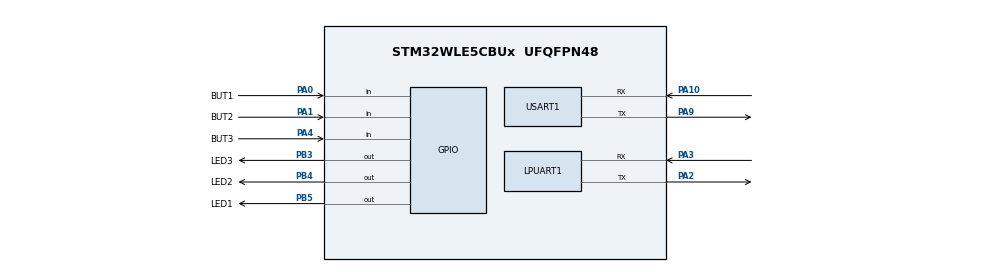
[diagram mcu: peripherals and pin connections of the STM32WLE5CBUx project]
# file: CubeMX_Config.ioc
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Mcu.Family=STM32WL
Mcu.Name=STM32WLE5CBUx
Mcu.Package=UFQFPN48
NVIC.PriorityGroup=NVIC_PRIORITYGROUP_4
PA0.GPIO_Label=BUT1
PA0.Signal=GPIO_Input
PA1.GPIO_Label=BUT2
PA1.Signal=GPIO_Input
PA10.Mode=Asynchronous
PA10.Signal=USART1_RX
PA2.GPIO_PuPd=GPIO_PULLUP
PA2.Mode=Asynchronous
PA2.Signal=LPUART1_TX
PA3.GPIO_PuPd=GPIO_PULLUP
PA3.Mode=Asynchronous
PA3.Signal=LPUART1_RX
PA4.GPIO_Label=BUT3
PA4.Signal=GPIO_Input
PA9.Mode=Asynchronous
PA9.Signal=USART1_TX
PB3.GPIO_Label=LED3
PB3.Signal=GPIO_Output
PB4.GPIO_Label=LED2
PB4.Signal=GPIO_Output
PB5.GPIO_Label=LED1
PB5.Signal=GPIO_Output
ProjectManager.HeapSize=0x200
ProjectManager.StackSize=0x400
ProjectManager.TargetToolchain=MDK-ARM V5.32
RCC.AHBFreq_Value=48000000
RCC.APB1Freq_Value=48000000
RCC.APB1TimFreq_Value=48000000
RCC.APB2Freq_Value=48000000
RCC.APB2TimFreq_Value=48000000
RCC.APB3Freq_Value=48000000
RCC.CortexFreq_Value=48000000
RCC.HCLKFreq_Value=48000000
RCC.HSE_VALUE=8000000
RCC.HSI_VALUE=16000000
RCC.LSE_VALUE=32768
RCC.MSIClockRange=RCC_MSIRANGE_11
RCC.SYSCLKFreq_VALUE=48000000
RCC.USART1CLockSelection=RCC_USART1CLKSOURCE_SYSCLK
RCC.USART2CLockSelection=RCC_USART2CLKSOURCE_SYSCLK
RCC.VCOOutputFreq_Value=384000000
USART1.VirtualMode-Asynchronous=VM_ASYNC
board=custom

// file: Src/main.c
/* USER CODE BEGIN Header */
/**
  ******************************************************************************
  * @file           : main.c
  * @brief          : Main program body
  ******************************************************************************
  * @attention
  *
  * <h2><center>&copy; Copyright (c) 2021 STMicroelectronics.
  * All rights reserved.</center></h2>
  *
  * This software component is licensed by ST under BSD 3-Clause license,
  * the "License"; You may not use this file except in compliance with the
  * License. You may obtain a copy of the License at:
  *                        opensource.org/licenses/BSD-3-Clause
  *
  ******************************************************************************
  */
/* USER CODE END Header */
#include "main.h"

/* USER CODE BEGIN Includes */
#include "main.h"
#include "stm32wlxx_hal.h"
#include "app_lorawan.h"

/* USER CODE END Includes */

UART_HandleTypeDef hlpuart1;
UART_HandleTypeDef huart1;

void SystemClock_Config(void);
static void MX_GPIO_Init(void);
static void MX_USART1_UART_Init(void);
static void MX_LPUART1_UART_Init(void);

int main(void)
{

  /* MCU Configuration--------------------------------------------------------*/

  /* Reset of all peripherals, Initializes the Flash interface and the Systick. */
  HAL_Init();

  /* Configure the system clock */
  SystemClock_Config();

  /* Initialize all configured peripherals */
  MX_GPIO_Init();
  MX_USART1_UART_Init();
  MX_LPUART1_UART_Init();

  /* Infinite loop */
  /* USER CODE BEGIN WHILE */
  while (1)
  {
    MX_LoRaWAN_Process();
  }
    /* USER CODE END WHILE */

}

void SystemClock_Config(void)
{
  RCC_OscInitTypeDef RCC_OscInitStruct = {0};
  RCC_ClkInitTypeDef RCC_ClkInitStruct = {0};

  /** Configure the main internal regulator output voltage
  */
  __HAL_PWR_VOLTAGESCALING_CONFIG(PWR_REGULATOR_VOLTAGE_SCALE1);
  /** Initializes the CPU, AHB and APB busses clocks
  */
  RCC_OscInitStruct.OscillatorType = RCC_OSCILLATORTYPE_MSI;
  RCC_OscInitStruct.MSIState = RCC_MSI_ON;
  RCC_OscInitStruct.MSICalibrationValue = RCC_MSICALIBRATION_DEFAULT;
  RCC_OscInitStruct.MSIClockRange = RCC_MSIRANGE_11;
  RCC_OscInitStruct.PLL.PLLState = RCC_PLL_NONE;
  if (HAL_RCC_OscConfig(&RCC_OscInitStruct) != HAL_OK)
  {
    Error_Handler();
  }
  /** Configure the SYSCLKSource, HCLK, PCLK1 and PCLK2 clocks dividers
  */
  RCC_ClkInitStruct.ClockType = RCC_CLOCKTYPE_HCLK3|RCC_CLOCKTYPE_HCLK
                              |RCC_CLOCKTYPE_SYSCLK|RCC_CLOCKTYPE_PCLK1
                              |RCC_CLOCKTYPE_PCLK2;
  RCC_ClkInitStruct.SYSCLKSource = RCC_SYSCLKSOURCE_MSI;
  RCC_ClkInitStruct.AHBCLKDivider = RCC_SYSCLK_DIV1;
  RCC_ClkInitStruct.APB1CLKDivider = RCC_HCLK_DIV1;
  RCC_ClkInitStruct.APB2CLKDivider = RCC_HCLK_DIV1;
  RCC_ClkInitStruct.AHBCLK3Divider = RCC_SYSCLK_DIV1;

  if (HAL_RCC_ClockConfig(&RCC_ClkInitStruct, FLASH_LATENCY_2) != HAL_OK)
  {
    Error_Handler();
  }
}

static void MX_LPUART1_UART_Init(void)
{

  hlpuart1.Instance = LPUART1;
  hlpuart1.Init.BaudRate = 209700;
  hlpuart1.Init.WordLength = UART_WORDLENGTH_8B;
  hlpuart1.Init.StopBits = UART_STOPBITS_1;
  hlpuart1.Init.Parity = UART_PARITY_NONE;
  hlpuart1.Init.Mode = UART_MODE_TX_RX;
  hlpuart1.Init.HwFlowCtl = UART_HWCONTROL_NONE;
  hlpuart1.Init.OneBitSampling = UART_ONE_BIT_SAMPLE_DISABLE;
  hlpuart1.Init.ClockPrescaler = UART_PRESCALER_DIV1;
  hlpuart1.AdvancedInit.AdvFeatureInit = UART_ADVFEATURE_NO_INIT;
  hlpuart1.FifoMode = UART_FIFOMODE_DISABLE;
  if (HAL_UART_Init(&hlpuart1) != HAL_OK)
  {
    Error_Handler();
  }
  if (HAL_UARTEx_SetTxFifoThreshold(&hlpuart1, UART_TXFIFO_THRESHOLD_1_8) != HAL_OK)
  {
    Error_Handler();
  }
  if (HAL_UARTEx_SetRxFifoThreshold(&hlpuart1, UART_RXFIFO_THRESHOLD_1_8) != HAL_OK)
  {
    Error_Handler();
  }
  if (HAL_UARTEx_DisableFifoMode(&hlpuart1) != HAL_OK)
  {
    Error_Handler();
  }

}

static void MX_USART1_UART_Init(void)
{

  huart1.Instance = USART1;
  huart1.Init.BaudRate = 115200;
  huart1.Init.WordLength = UART_WORDLENGTH_8B;
  huart1.Init.StopBits = UART_STOPBITS_1;
  huart1.Init.Parity = UART_PARITY_NONE;
  huart1.Init.Mode = UART_MODE_TX_RX;
  huart1.Init.HwFlowCtl = UART_HWCONTROL_NONE;
  huart1.Init.OverSampling = UART_OVERSAMPLING_16;
  huart1.Init.OneBitSampling = UART_ONE_BIT_SAMPLE_DISABLE;
  huart1.Init.ClockPrescaler = UART_PRESCALER_DIV1;
  huart1.AdvancedInit.AdvFeatureInit = UART_ADVFEATURE_NO_INIT;
  if (HAL_UART_Init(&huart1) != HAL_OK)
  {
    Error_Handler();
  }
  if (HAL_UARTEx_SetTxFifoThreshold(&huart1, UART_TXFIFO_THRESHOLD_1_8) != HAL_OK)
  {
    Error_Handler();
  }
  if (HAL_UARTEx_SetRxFifoThreshold(&huart1, UART_RXFIFO_THRESHOLD_1_8) != HAL_OK)
  {
    Error_Handler();
  }
  if (HAL_UARTEx_DisableFifoMode(&huart1) != HAL_OK)
  {
    Error_Handler();
  }

}

static void MX_GPIO_Init(void)
{
  GPIO_InitTypeDef GPIO_InitStruct = {0};

  /* GPIO Ports Clock Enable */
  __HAL_RCC_GPIOB_CLK_ENABLE();
  __HAL_RCC_GPIOA_CLK_ENABLE();

  /*Configure GPIO pin Output Level */
  HAL_GPIO_WritePin(GPIOB, LED3_Pin|LED2_Pin|LED1_Pin, GPIO_PIN_RESET);

  /*Configure GPIO pins : LED3_Pin LED2_Pin LED1_Pin */
  GPIO_InitStruct.Pin = LED3_Pin|LED2_Pin|LED1_Pin;
  GPIO_InitStruct.Mode = GPIO_MODE_OUTPUT_PP;
  GPIO_InitStruct.Pull = GPIO_NOPULL;
  GPIO_InitStruct.Speed = GPIO_SPEED_FREQ_LOW;
  HAL_GPIO_Init(GPIOB, &GPIO_InitStruct);

  /*Configure GPIO pins : BUT1_Pin BUT2_Pin BUT3_Pin */
  GPIO_InitStruct.Pin = BUT1_Pin|BUT2_Pin|BUT3_Pin;
  GPIO_InitStruct.Mode = GPIO_MODE_INPUT;
  GPIO_InitStruct.Pull = GPIO_NOPULL;
  HAL_GPIO_Init(GPIOA, &GPIO_InitStruct);

}

void Error_Handler(void)
{
  while (1)
  {
  }
}

/************************ (C) COPYRIGHT STMicroelectronics *****END OF FILE****/
